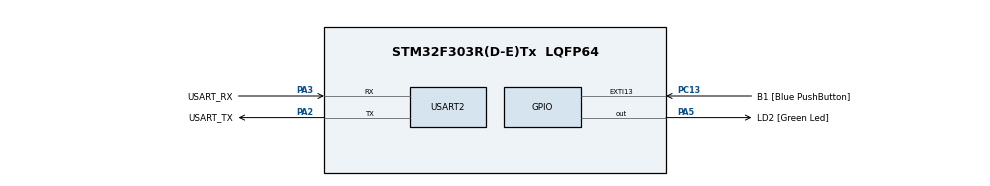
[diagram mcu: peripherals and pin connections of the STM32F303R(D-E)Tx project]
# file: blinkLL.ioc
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Mcu.Family=STM32F3
Mcu.Name=STM32F303R(D-E)Tx
Mcu.Package=LQFP64
NVIC.PriorityGroup=NVIC_PRIORITYGROUP_0
PA13.GPIO_Label=TMS
PA13.Mode=Serial_Wire
PA13.Signal=SYS_JTMS-SWDIO
PA14.GPIO_Label=TCK
PA14.Mode=Serial_Wire
PA14.Signal=SYS_JTCK-SWCLK
PA2.GPIO_Label=USART_TX
PA2.GPIO_Mode=GPIO_MODE_AF_PP
PA2.GPIO_PuPd=GPIO_NOPULL
PA2.GPIO_Speed=GPIO_SPEED_FREQ_LOW
PA2.Mode=Asynchronous
PA2.Signal=USART2_TX
PA3.GPIO_Label=USART_RX
PA3.GPIO_Mode=GPIO_MODE_AF_PP
PA3.GPIO_PuPd=GPIO_NOPULL
PA3.GPIO_Speed=GPIO_SPEED_FREQ_LOW
PA3.Mode=Asynchronous
PA3.Signal=USART2_RX
PA5.GPIO_Label=LD2 [Green Led]
PA5.GPIO_Mode=GPIO_MODE_OUTPUT_PP
PA5.GPIO_PuPd=GPIO_NOPULL
PA5.GPIO_Speed=GPIO_SPEED_FREQ_LOW
PA5.Signal=GPIO_Output
PB3.GPIO_Label=SWO
PB3.Signal=SYS_JTDO-TRACESWO
PC13.GPIO_Label=B1 [Blue PushButton]
PC13.GPIO_ModeDefaultEXTI=GPIO_MODE_IT_FALLING
PC13.Signal=GPXTI13
PC14-OSC32_IN.Mode=LSE-External-Oscillator
PC14-OSC32_IN.Signal=RCC_OSC32_IN
PC15-OSC32_OUT.Mode=LSE-External-Oscillator
PC15-OSC32_OUT.Signal=RCC_OSC32_OUT
PF0-OSC_IN.Mode=HSE-External-Clock-Source
PF0-OSC_IN.Signal=RCC_OSC_IN
PF1-OSC_OUT.Signal=RCC_OSC_OUT
ProjectManager.HeapSize=0x200
ProjectManager.StackSize=0x400
ProjectManager.TargetToolchain=TrueSTUDIO
RCC.AHBFreq_Value=72000000
RCC.APB1CLKDivider=RCC_HCLK_DIV2
RCC.APB1Freq_Value=36000000
RCC.APB1TimFreq_Value=72000000
RCC.APB2Freq_Value=72000000
RCC.APB2TimFreq_Value=72000000
RCC.CortexFreq_Value=72000000
RCC.HCLKFreq_Value=72000000
RCC.HSE_VALUE=8000000
RCC.HSI_VALUE=8000000
RCC.PLLM=8
RCC.PLLMUL=RCC_PLL_MUL9
RCC.PLLN=336
RCC.PLLP=RCC_PLLP_DIV4
RCC.PLLQ=7
RCC.RCC_PLLsource_Clock_Source_FROM_HSE=RCC_HSE_PREDIV_DIV2
RCC.SYSCLKFreq_VALUE=72000000
RCC.SYSCLKSourceVirtual=RCC_SYSCLKSOURCE_PLLCLK
RCC.USBFreq_Value=72000000
USART2.VirtualMode-Asynchronous=VM_ASYNC
board=NUCLEO-F303RE

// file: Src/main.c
/* USER CODE BEGIN Header */
/**
  ******************************************************************************
  * @file           : main.c
  * @brief          : Main program body
  ******************************************************************************
  * @attention
  *
  * <h2><center>&copy; Copyright (c) 2019 STMicroelectronics.
  * All rights reserved.</center></h2>
  *
  * This software component is licensed by ST under BSD 3-Clause license,
  * the "License"; You may not use this file except in compliance with the
  * License. You may obtain a copy of the License at:
  *                        opensource.org/licenses/BSD-3-Clause
  *
  ******************************************************************************
  */
/* USER CODE END Header */

#include "main.h"
#include "usart.h"
#include "gpio.h"

void SystemClock_Config(void);

int main(void)
{
  /* USER CODE BEGIN 1 */
	volatile int k1,k2,k3;
  /* USER CODE END 1 */

  /* MCU Configuration--------------------------------------------------------*/

  /* Reset of all peripherals, Initializes the Flash interface and the Systick. */

  LL_APB2_GRP1_EnableClock(LL_APB2_GRP1_PERIPH_SYSCFG);
  LL_APB1_GRP1_EnableClock(LL_APB1_GRP1_PERIPH_PWR);

  NVIC_SetPriorityGrouping(NVIC_PRIORITYGROUP_0);

  /* System interrupt init*/

  /* Configure the system clock */
  SystemClock_Config();

  /* Initialize all configured peripherals */
  MX_GPIO_Init();
  MX_USART2_UART_Init();

  /* Infinite loop */
  while (1)
  {

    /* USER CODE BEGIN 3 */
	  LL_GPIO_TogglePin(LD2_GPIO_Port, LD2_Pin);
	  for(k1=0;k1<=1000;k1++){
		  for(k2=0;k2<=1000;k2++){
			  k3++;
		  }
	  }
	  LL_GPIO_TogglePin(LD2_GPIO_Port, LD2_Pin);
	  for(k1=0;k1<=1000;k1++){
		  for(k2=0;k2<=1000;k2++){
			  k3++;
		  }
	  }
	  //LL_GPIO_ResetOutputPin(LD2_GPIO_Port, LD2_Pin);
	  //LL_GPIO_WriteOutputPort()
	  //delay(500);
  }
  /* USER CODE END 3 */
}

void SystemClock_Config(void)
{
  LL_FLASH_SetLatency(LL_FLASH_LATENCY_2);

   if(LL_FLASH_GetLatency() != LL_FLASH_LATENCY_2)
  {
  Error_Handler();
  }
  LL_RCC_HSI_Enable();

   /* Wait till HSI is ready */
  while(LL_RCC_HSI_IsReady() != 1)
  {

  }
  LL_RCC_HSI_SetCalibTrimming(16);
  LL_RCC_PLL_ConfigDomain_SYS(LL_RCC_PLLSOURCE_HSI, LL_RCC_PLL_MUL_9, LL_RCC_PREDIV_DIV_1);
  LL_RCC_PLL_Enable();

   /* Wait till PLL is ready */
  while(LL_RCC_PLL_IsReady() != 1)
  {

  }
  LL_RCC_SetAHBPrescaler(LL_RCC_SYSCLK_DIV_1);
  LL_RCC_SetAPB1Prescaler(LL_RCC_APB1_DIV_2);
  LL_RCC_SetAPB2Prescaler(LL_RCC_APB1_DIV_1);
  LL_RCC_SetSysClkSource(LL_RCC_SYS_CLKSOURCE_PLL);

   /* Wait till System clock is ready */
  while(LL_RCC_GetSysClkSource() != LL_RCC_SYS_CLKSOURCE_STATUS_PLL)
  {

  }
  LL_Init1msTick(72000000);
  LL_SYSTICK_SetClkSource(LL_SYSTICK_CLKSOURCE_HCLK);
  LL_SetSystemCoreClock(72000000);
  LL_RCC_SetUSARTClockSource(LL_RCC_USART2_CLKSOURCE_PCLK1);
}

void Error_Handler(void)
{
}

/************************ (C) COPYRIGHT STMicroelectronics *****END OF FILE****/
